# MAX32600 register map
File version: 1.0
Registers are 32-bit, read-write, reset 0x0 unless marked. A register's access mark holds for its fields unless they carry their own. Offsets are from the block's base; [hi:lo] are bit positions.

## SPI0 — SPI Master Interface
Base 0x40030000
Same registers: SPI1 0x40031000, SPI2 0x40032000
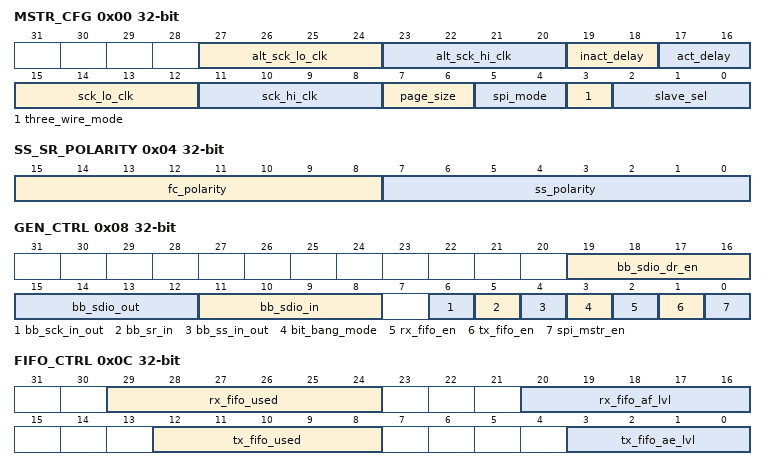
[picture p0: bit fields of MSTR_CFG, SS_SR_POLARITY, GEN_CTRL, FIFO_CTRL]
0x00 MSTR_CFG — SPI Master Configuration Register
  [27:24] alt_sck_lo_clk — Alt SCK Low Clocks
  [23:20] alt_sck_hi_clk — Alt SCK High Clocks
  [19:18] inact_delay — SS Inactive Timing
  [17:16] act_delay — SS Active Timing
  [15:12] sck_lo_clk — SCK Low Clocks
  [11:8] sck_hi_clk — SCK High Clocks
  [7:6] page_size
  [5:4] spi_mode
  [3] three_wire_mode — 3-Wire Mode
  [2:0] slave_sel — SPI Slave Select
0x04 SS_SR_POLARITY — Polarity Control for SS and SR Signals
  [15:8] fc_polarity — SR Signal Polarity [FC Polarity]
  [7:0] ss_polarity — SS Signal Polarity
0x08 GEN_CTRL — SPI Master General Control Register
  [19:16] bb_sdio_dr_en — Bit Bang SDIO Drive Enable
  [15:12] bb_sdio_out — Bit Bang SDIO Output
  [11:8] bb_sdio_in ro — Bit Bang SDIO Input
  [6] bb_sck_in_out — Bit Bang SCK Input/Output
  [5] bb_sr_in ro — Bit Bang SR Input
  [4] bb_ss_in_out — Bit Bang SS Input/Output
  [3] bit_bang_mode — Bit Bang Mode Enable
  [2] rx_fifo_en — Results FIFO Enable
  [1] tx_fifo_en — Transaction FIFO Enable
  [0] spi_mstr_en — Enable/Disable SPI Master
0x0C FIFO_CTRL — SPI Master FIFO Control Register
  [29:24] rx_fifo_used ro — Results FIFO Used
  [20:16] rx_fifo_af_lvl — Results FIFO AF Level
  [12:8] tx_fifo_used ro — Transaction FIFO Used
  [3:0] tx_fifo_ae_lvl — Transaction FIFO AE Level
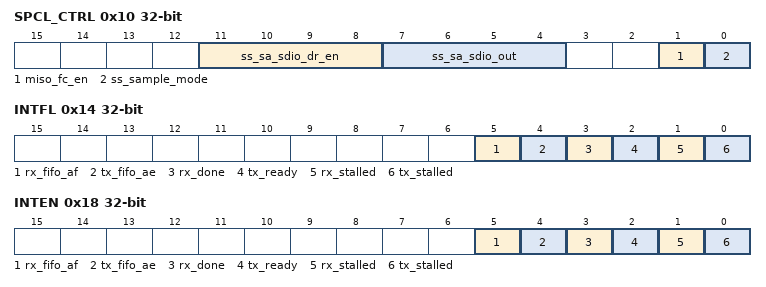
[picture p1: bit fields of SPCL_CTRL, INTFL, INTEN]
0x10 SPCL_CTRL — SPI Master Special Mode Controls
  [11:8] ss_sa_sdio_dr_en — SDIO Active Drive Mode
  [7:4] ss_sa_sdio_out — SDIO Active Output Value
  [1] miso_fc_en — SDIO(1) to SR(0) Mode
  [0] ss_sample_mode
0x14 INTFL — SPI Master Interrupt Flags
  [5] rx_fifo_af write-1-clears — RXFIFO Almost Full Int Status
  [4] tx_fifo_ae write-1-clears — TXFIFO Almost Empty Int Status
  [3] rx_done write-1-clears — Results Done Int Status
  [2] tx_ready write-1-clears — Transaction Ready Int Status
  [1] rx_stalled write-1-clears — Results Stalled Int Status
  [0] tx_stalled write-1-clears — Transaction Stalled Int Status
0x18 INTEN — SPI Master Interrupt Enable/Disable Settings
  [5] rx_fifo_af — RXFIFO Almost Full Int Enable
  [4] tx_fifo_ae — TXFIFO Almost Empty Int Enable
  [3] rx_done — Results Done Int Enable
  [2] tx_ready — Transaction Ready Int Enable
  [1] rx_stalled — Results Stalled Int Enable
  [0] tx_stalled — Transaction Stalled Int Enable

## UART0 — UART / Serial Port Interface (Wasp-type)
Base 0x40038000
Same registers: UART1 0x40039000
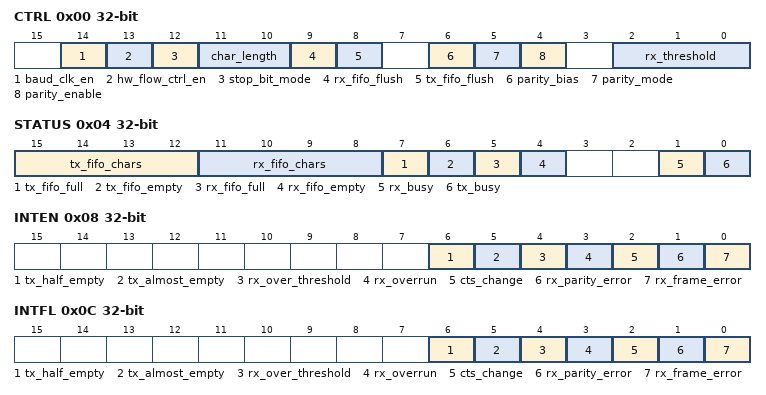
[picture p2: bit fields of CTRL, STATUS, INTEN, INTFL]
0x00 CTRL — UART Control Register
  [14] baud_clk_en — Baud Clock Generation Enable
  [13] hw_flow_ctrl_en — Hardware Flow Control Enable
  [12] stop_bit_mode — Stop Bit Mode Select
  [11:10] char_length — Character Transfer Bit Length
  [9] rx_fifo_flush wo — Receive FIFO Flush
  [8] tx_fifo_flush wo — Transmit FIFO Flush
  [6] parity_bias — Parity Basis Select
  [5] parity_mode — Parity Mode Select
  [4] parity_enable
  [2:0] rx_threshold — Receive FIFO Interrupt Threshold
0x04 STATUS — UART Status Register
  [15:12] tx_fifo_chars ro — TX FIFO Chars Used
  [11:8] rx_fifo_chars ro — RX FIFO Chars Used
  [7] tx_fifo_full ro
  [6] tx_fifo_empty ro
  [5] rx_fifo_full ro
  [4] rx_fifo_empty ro
  [1] rx_busy ro
  [0] tx_busy ro
0x08 INTEN — Interrupt Enable/Disable Controls
  [6] tx_half_empty — TX FIFO Half Empty Int Enable
  [5] tx_almost_empty — TX FIFO Almost Empty Int Enable
  [4] rx_over_threshold — RX FIFO Over Threshold Int Enable
  [3] rx_overrun — RX Overrun Interrupt Enable
  [2] cts_change — CTS Value Change Interrupt Enable
  [1] rx_parity_error — RX Parity Error Interrupt Enable
  [0] rx_frame_error — RX Frame Error Interrupt Enable
0x0C INTFL — Interrupt Flags
  [6] tx_half_empty write-0-clears — TX FIFO Half Empty Int Status
  [5] tx_almost_empty write-0-clears — TX FIFO Almost Empty Int Status
  [4] rx_over_threshold write-0-clears — RX FIFO Over Threshold Int Status
  [3] rx_overrun write-0-clears — RX Overrun Interrupt Status
  [2] cts_change write-0-clears — CTS Value Change Interrupt Status
  [1] rx_parity_error write-0-clears — RX Parity Error Interrupt Status
  [0] rx_frame_error write-0-clears — RX Frame Error Interrupt Status
0x10 BAUD_INT — Baud Rate Setting (Integer Portion)
  [11:0] fbaud — Integer portion of baudrate DIV.
0x14 BAUD_DIV_128 — Baud Rate Setting (Div 128 Decimal Portion)
  [6:0] div — Decimal portion of baudrate DIV.
0x18 TX_FIFO_OUT — TX FIFO Output End (read-only)
  [7:0] tx_fifo ro — TX FIFO Output
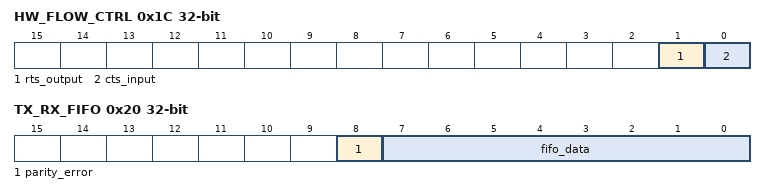
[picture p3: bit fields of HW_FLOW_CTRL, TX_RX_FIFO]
0x1C HW_FLOW_CTRL — Hardware Flow Control Register
  [1] rts_output — RTS Output Value
  [0] cts_input ro — CTS Input Value
0x20 TX_RX_FIFO — [DR] Write to load TX FIFO, Read to unload RX FIFO
  [8] parity_error ro — Parity Error Flag
  [7:0] fifo_data — TX/RX FIFO Data
